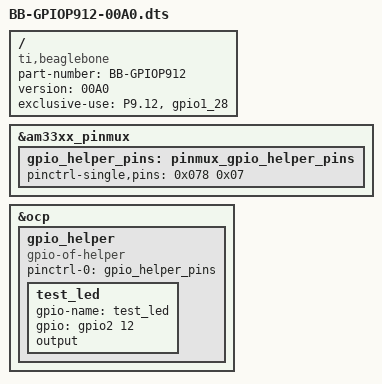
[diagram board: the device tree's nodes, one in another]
/* Copyright (C) 2013 Pantelis Antoniou <pa...@antoniou-consulting.com>
*
* This program is free software; you can redistribute it and/or modify
* it under the terms of the GNU General Public License version 2 as
* published by the Free Software Foundation.
*/
/dts-v1/;
/plugin/;

/ {
	compatible = "ti,beaglebone", "ti,beaglebone-black";

	/* identification */
	part-number = "BB-GPIOP912";
	version = "00A0";

	/* state the resources this cape uses */
	exclusive-use =
		/* the pin header uses */
		"P9.12",	/* gpio */
		/* the hardware IP uses */
		"gpio1_28";

	fragment@0 {
		target = <&am33xx_pinmux>;
		__overlay__ {
			gpio_helper_pins: pinmux_gpio_helper_pins {
				pinctrl-single,pins = <
					0x078 0x07 	/* P9.12 GPIO1_28:  MODE7 | OUTPUT */
				>;
			};
		};	
	};

	fragment@2 {
		target = <&ocp>;
		__overlay__ {

			gpio_helper {
				compatible = "gpio-of-helper";
				status = "okay";
				pinctrl-names = "default";
				pinctrl-0 = <&gpio_helper_pins>;

				/* declare your gpios */
				test_led {
					gpio-name = "test_led";
					gpio = <&gpio2 12 0x00>;	/* gpio2 is gpio1 */
					output;
				};

			};
		};
	};
};
